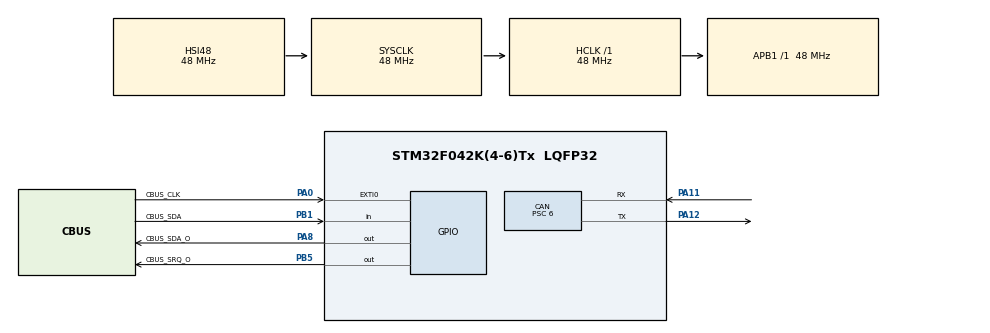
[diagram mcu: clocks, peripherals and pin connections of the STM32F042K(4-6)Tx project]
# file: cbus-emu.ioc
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CAN.BS1=CAN_BS1_13TQ
CAN.BS2=CAN_BS2_2TQ
CAN.CalculateBaudRate=500000
CAN.CalculateTimeBit=2000
CAN.CalculateTimeQuantum=125.0
CAN.Prescaler=6
Mcu.Family=STM32F0
Mcu.Name=STM32F042K(4-6)Tx
Mcu.Package=LQFP32
NVIC.EXTI0_1_IRQn=true\:0\:0\:false\:false\:false\:true\:false\:true
PA0.GPIO_Label=CBUS_CLK
PA0.GPIO_ModeDefaultEXTI=GPIO_MODE_IT_FALLING
PA0.Signal=GPXTI0
PA11.Mode=CAN_Activate
PA11.Signal=CAN_RX
PA12.Mode=CAN_Activate
PA12.Signal=CAN_TX
PA8.GPIO_Label=CBUS_SDA_O
PA8.GPIO_PuPd=GPIO_PULLDOWN
PA8.GPIO_Speed=GPIO_SPEED_FREQ_HIGH
PA8.Signal=GPIO_Output
PB1.GPIO_Label=CBUS_SDA
PB1.Signal=GPIO_Input
PB5.GPIO_Label=CBUS_SRQ_O
PB5.GPIO_PuPd=GPIO_PULLDOWN
PB5.GPIO_Speed=GPIO_SPEED_FREQ_HIGH
PB5.Signal=GPIO_Output
PF0-OSC_IN.Mode=HSE-External-Clock-Source
PF0-OSC_IN.Signal=RCC_OSC_IN
ProjectManager.HeapSize=0x200
ProjectManager.StackSize=0x400
ProjectManager.TargetToolchain=STM32CubeIDE
RCC.AHBFreq_Value=48000000
RCC.APB1Freq_Value=48000000
RCC.APB1TimFreq_Value=48000000
RCC.HCLKFreq_Value=48000000
RCC.PLLSourceVirtual=RCC_PLLSOURCE_HSI48
RCC.SYSCLKFreq_VALUE=48000000
RCC.SYSCLKSource=RCC_SYSCLKSOURCE_HSI48
TIM2.Prescaler=48-1
VP_TIM2_VS_ClockSourceINT.Mode=Internal
board=NUCLEO-F042K6

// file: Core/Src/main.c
/* USER CODE BEGIN Header */
/**
  ******************************************************************************
  * @file           : main.c
  * @brief          : Main program body
  ******************************************************************************
  * @attention
  *
  * Copyright (c) 2022 STMicroelectronics.
  * All rights reserved.
  *
  * This software is licensed under terms that can be found in the LICENSE file
  * in the root directory of this software component.
  * If no LICENSE file comes with this software, it is provided AS-IS.
  *
  ******************************************************************************
  */
/* USER CODE END Header */
#include "main.h"

/* USER CODE BEGIN Includes */
#include "cbus.h"
/* USER CODE END Includes */

 CAN_HandleTypeDef hcan;

TIM_HandleTypeDef htim2;

void SystemClock_Config(void);
static void MX_GPIO_Init(void);
static void MX_TIM2_Init(void);
static void MX_CAN_Init(void);

int main(void)
{

  /* MCU Configuration--------------------------------------------------------*/

  /* Reset of all peripherals, Initializes the Flash interface and the Systick. */
  HAL_Init();

  /* Configure the system clock */
  SystemClock_Config();

  /* Initialize all configured peripherals */
  MX_GPIO_Init();
  MX_TIM2_Init();
  MX_CAN_Init();
  /* USER CODE BEGIN 2 */
  CBUS_main();
  /* USER CODE END 2 */

  /* Infinite loop */
  /* USER CODE BEGIN WHILE */

  while (1)
  {
    CBUS_tick();
    /* USER CODE END WHILE */

  }
}

void SystemClock_Config(void)
{
  RCC_OscInitTypeDef RCC_OscInitStruct = {0};
  RCC_ClkInitTypeDef RCC_ClkInitStruct = {0};

  /** Initializes the RCC Oscillators according to the specified parameters
  * in the RCC_OscInitTypeDef structure.
  */
  RCC_OscInitStruct.OscillatorType = RCC_OSCILLATORTYPE_HSI48;
  RCC_OscInitStruct.HSI48State = RCC_HSI48_ON;
  RCC_OscInitStruct.PLL.PLLState = RCC_PLL_NONE;
  if (HAL_RCC_OscConfig(&RCC_OscInitStruct) != HAL_OK)
  {
    Error_Handler();
  }

  /** Initializes the CPU, AHB and APB buses clocks
  */
  RCC_ClkInitStruct.ClockType = RCC_CLOCKTYPE_HCLK|RCC_CLOCKTYPE_SYSCLK
                              |RCC_CLOCKTYPE_PCLK1;
  RCC_ClkInitStruct.SYSCLKSource = RCC_SYSCLKSOURCE_HSI48;
  RCC_ClkInitStruct.AHBCLKDivider = RCC_SYSCLK_DIV1;
  RCC_ClkInitStruct.APB1CLKDivider = RCC_HCLK_DIV1;

  if (HAL_RCC_ClockConfig(&RCC_ClkInitStruct, FLASH_LATENCY_1) != HAL_OK)
  {
    Error_Handler();
  }
}

static void MX_CAN_Init(void)
{

  hcan.Instance = CAN;
  hcan.Init.Prescaler = 6;
  hcan.Init.Mode = CAN_MODE_NORMAL;
  hcan.Init.SyncJumpWidth = CAN_SJW_1TQ;
  hcan.Init.TimeSeg1 = CAN_BS1_13TQ;
  hcan.Init.TimeSeg2 = CAN_BS2_2TQ;
  hcan.Init.TimeTriggeredMode = DISABLE;
  hcan.Init.AutoBusOff = DISABLE;
  hcan.Init.AutoWakeUp = DISABLE;
  hcan.Init.AutoRetransmission = DISABLE;
  hcan.Init.ReceiveFifoLocked = DISABLE;
  hcan.Init.TransmitFifoPriority = DISABLE;
  if (HAL_CAN_Init(&hcan) != HAL_OK)
  {
    Error_Handler();
  }

}

static void MX_TIM2_Init(void)
{

  TIM_ClockConfigTypeDef sClockSourceConfig = {0};
  TIM_MasterConfigTypeDef sMasterConfig = {0};

  htim2.Instance = TIM2;
  htim2.Init.Prescaler = 48-1;
  htim2.Init.CounterMode = TIM_COUNTERMODE_UP;
  htim2.Init.Period = 4294967295;
  htim2.Init.ClockDivision = TIM_CLOCKDIVISION_DIV1;
  htim2.Init.AutoReloadPreload = TIM_AUTORELOAD_PRELOAD_DISABLE;
  if (HAL_TIM_Base_Init(&htim2) != HAL_OK)
  {
    Error_Handler();
  }
  sClockSourceConfig.ClockSource = TIM_CLOCKSOURCE_INTERNAL;
  if (HAL_TIM_ConfigClockSource(&htim2, &sClockSourceConfig) != HAL_OK)
  {
    Error_Handler();
  }
  sMasterConfig.MasterOutputTrigger = TIM_TRGO_RESET;
  sMasterConfig.MasterSlaveMode = TIM_MASTERSLAVEMODE_DISABLE;
  if (HAL_TIMEx_MasterConfigSynchronization(&htim2, &sMasterConfig) != HAL_OK)
  {
    Error_Handler();
  }

}

static void MX_GPIO_Init(void)
{
  GPIO_InitTypeDef GPIO_InitStruct = {0};

  /* GPIO Ports Clock Enable */
  __HAL_RCC_GPIOF_CLK_ENABLE();
  __HAL_RCC_GPIOA_CLK_ENABLE();
  __HAL_RCC_GPIOB_CLK_ENABLE();

  /*Configure GPIO pin Output Level */
  HAL_GPIO_WritePin(CBUS_SDA_O_GPIO_Port, CBUS_SDA_O_Pin, GPIO_PIN_RESET);

  /*Configure GPIO pin Output Level */
  HAL_GPIO_WritePin(CBUS_SRQ_O_GPIO_Port, CBUS_SRQ_O_Pin, GPIO_PIN_RESET);

  /*Configure GPIO pin : CBUS_CLK_Pin */
  GPIO_InitStruct.Pin = CBUS_CLK_Pin;
  GPIO_InitStruct.Mode = GPIO_MODE_IT_FALLING;
  GPIO_InitStruct.Pull = GPIO_NOPULL;
  HAL_GPIO_Init(CBUS_CLK_GPIO_Port, &GPIO_InitStruct);

  /*Configure GPIO pin : CBUS_SDA_Pin */
  GPIO_InitStruct.Pin = CBUS_SDA_Pin;
  GPIO_InitStruct.Mode = GPIO_MODE_INPUT;
  GPIO_InitStruct.Pull = GPIO_NOPULL;
  HAL_GPIO_Init(CBUS_SDA_GPIO_Port, &GPIO_InitStruct);

  /*Configure GPIO pin : CBUS_SDA_O_Pin */
  GPIO_InitStruct.Pin = CBUS_SDA_O_Pin;
  GPIO_InitStruct.Mode = GPIO_MODE_OUTPUT_PP;
  GPIO_InitStruct.Pull = GPIO_PULLDOWN;
  GPIO_InitStruct.Speed = GPIO_SPEED_FREQ_HIGH;
  HAL_GPIO_Init(CBUS_SDA_O_GPIO_Port, &GPIO_InitStruct);

  /*Configure GPIO pin : CBUS_SRQ_O_Pin */
  GPIO_InitStruct.Pin = CBUS_SRQ_O_Pin;
  GPIO_InitStruct.Mode = GPIO_MODE_OUTPUT_PP;
  GPIO_InitStruct.Pull = GPIO_PULLDOWN;
  GPIO_InitStruct.Speed = GPIO_SPEED_FREQ_HIGH;
  HAL_GPIO_Init(CBUS_SRQ_O_GPIO_Port, &GPIO_InitStruct);

  /* EXTI interrupt init*/
  HAL_NVIC_SetPriority(EXTI0_1_IRQn, 0, 0);
  HAL_NVIC_EnableIRQ(EXTI0_1_IRQn);

}

void Error_Handler(void)
{
  __disable_irq();
  while (1)
  {
  }
}
